# H3 register map
Vendor: Allwinner; Series: H3; File version: 0.1
CPU: 0, little endian, MPU, no FPU, 0 interrupt priority bits
Registers are 32-bit, read-write, reset 0x0 unless marked. A register's access mark holds for its fields unless they carry their own. Offsets are from the block's base; [hi:lo] are bit positions.

## SD/MMC0
Base 0x01C0F000
Same registers: SD/MMC1 0x01C10000, SD/MMC2 0x01C11000
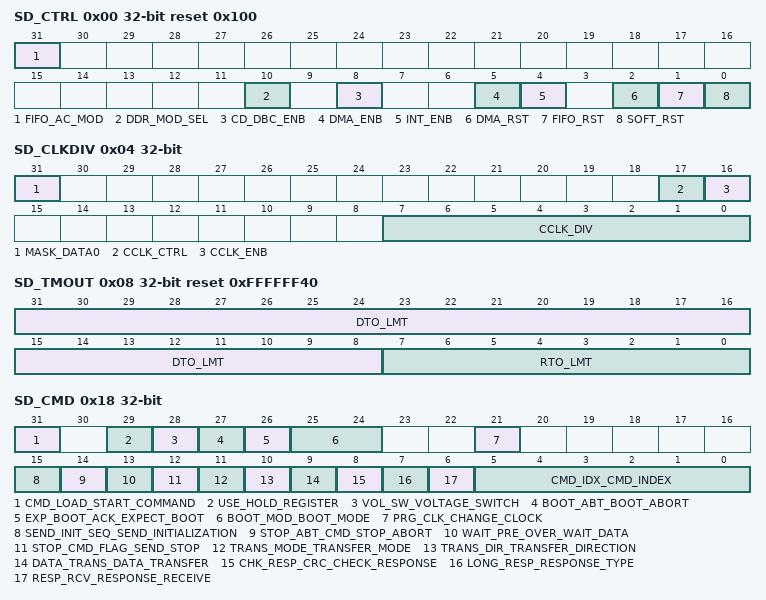
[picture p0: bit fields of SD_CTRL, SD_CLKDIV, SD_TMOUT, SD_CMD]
0x00 SD_CTRL reset 0x100
  [31] FIFO_AC_MOD — FIFO Access Mode 1-AHB bus 0-DMA bus
  [10] DDR_MOD_SEL — DDR Mode Select 0 - SDR mode 1 - DDR mode
  [8] CD_DBC_ENB — Card Detect (Data[3] status) De-bounce Enable 0 - disable de-bounce 1 - enable de-bounce
  [5] DMA_ENB — DMA Global Enable 0 - Disable DMA to transfer data, using AHB bus 1 - Enable DMA to transfer data
  [4] INT_ENB — Global Interrupt Enable 0 - Disable interrupts 1 - Enable interrupts
  [2] DMA_RST — DMA Reset
  [1] FIFO_RST — FIFO Reset 0 - No change 1 - Reset FIFO
  [0] SOFT_RST — Software Reset 0 - No change 1 - Reset SD/MMC controller
0x04 SD_CLKDIV
  [31] MASK_DATA0 — 0 - Do not mask data0 when updata clock ; 1 - Mask data0 when updata clock;
  [17] CCLK_CTRL — Card Clock Output Control 0 - Card clock always on 1 - Turn off card clock when FSM in IDLE state
  [16] CCLK_ENB — Card Clock Enable 0 - Card Clock off 1 - Card Clock on
  [7:0] CCLK_DIV — Card clock divider n - Source clock is divided by 2*n.(n=0~255)
0x08 SD_TMOUT reset 0xFFFFFF40
  [31:8] DTO_LMT — Data Timeout Limit
  [7:0] RTO_LMT — Response Timeout Limit
0x0C SD_CTYPE
  [1:0] CARD_WID — Card width 2`b00 - 1-bit width 2`b01 - 4-bit width 2`b1x - 8-bit width
0x10 SD_BLKSIZ reset 0x200
  [15:0] BLK_SZ — Block size
0x14 SD_BYTCNT reset 0x200
  [31:0] BYTE_CNT — Byte counter Number of bytes to be transferred; should be integer multiple of Block Size for block transfers.
0x18 SD_CMD
  [31] CMD_LOAD_START_COMMAND — CMD_LOAD Start Command. This bit is auto cleared when current command is sent. If there is no any response error happened, a command complete interrupt bit (CMD_OVER) will be set in interrupt register. You should not write any other command before this bit is cleared, or a command busy interrupt bit (CMD_BUSY) will be set in interrupt register.
  [29] USE_HOLD_REGISTER — Use Hold Register 0 - CMD and DATA sent to card bypassing HOLD Register 1 - CMD and DATA sent to card through the HOLD Register
  [28] VOL_SW_VOLTAGE_SWITCH — VOL_SW Voltage Switch 0 - normal command 1 - Voltage switch command, set for CMD11 only
  [27] BOOT_ABT_BOOT_ABORT — BOOT_ABT Boot Abort Setting this bit will terminate the boot operation.
  [26] EXP_BOOT_ACK_EXPECT_BOOT — EXP_BOOT_ACK Expect Boot Acknowledge. When Software sets this bit along in mandatory boot operation, controller expects a boot acknowledge start pattern of 0-1-0 from the selected card.
  [25:24] BOOT_MOD_BOOT_MODE — BOOT_MOD Boot Mode 2`b00 - normal command 2`b01 - Mandatory Boot operation 2`b10 - Alternate Boot operation 2`b11 - reserved
  [21] PRG_CLK_CHANGE_CLOCK — PRG_CLK Change Clock 0 - Normal command 1 - Change Card Clock; when this bit is set, controller will change clock domain and clock output. No command will be sent.
  [15] SEND_INIT_SEQ_SEND_INITIALIZATION — SEND_INIT_SEQ Send Initialization 0 - normal command sending 1 - Send initialization sequence before sending this command.
  [14] STOP_ABT_CMD_STOP_ABORT — STOP_ABT_CMD Stop Abort Command 0 - normal command sending 1 - send Stop or abort command to stop current data transfer in progress.(CMD12, CMD52 for writing `I/O Abort` in SDIO CCCR)
  [13] WAIT_PRE_OVER_WAIT_DATA — WAIT_PRE_OVER Wait Data Transfer Over 0 - Send command at once, do not care of data transferring 1 - Wait for data transfer completion before sending current command
  [12] STOP_CMD_FLAG_SEND_STOP — STOP_CMD_FLAG Send Stop CMD Automatically (CMD12) 0 - Do not send stop command at end of data transfer 1 - Send stop command automatically at end of data transfer
  [11] TRANS_MODE_TRANSFER_MODE — TRANS_MODE Transfer Mode 0 - Block data transfer command 1 - Stream data transfer command
  [10] TRANS_DIR_TRANSFER_DIRECTION — TRANS_DIR Transfer Direction 0 - Read operation 1 - Write operation
  [9] DATA_TRANS_DATA_TRANSFER — DATA_TRANS Data Transfer 0 - without data transfer 1 - with data transfer
  [8] CHK_RESP_CRC_CHECK_RESPONSE — CHK_RESP_CRC Check Response CRC 0 - Do not check response CRC 1 - Check response CRC
  [7] LONG_RESP_RESPONSE_TYPE — LONG_RESP Response Type 0 -Short Response (48 bits) 1 -Long Response (136 bits)
  [6] RESP_RCV_RESPONSE_RECEIVE — RESP_RCV Response Receive 0 - Command without Response 1 - Command with Response
  [5:0] CMD_IDX_CMD_INDEX — CMD_IDX CMD Index Command index value
0x1C SD_CMDARG
  [31:0] CMD_ARG — Command argument
0x20 SD_RESP0 — Response 0 register
  [31:0] CMD_RESP0 ro — response 0 Bit[31:0] of response
0x24 SD_RESP1 — Response 1 register
  [31:0] CMD_RESP1 ro — response 1 Bit[63:31] of response
0x28 SD_RESP2 — Response 2 register
  [31:0] CMD_RESP2 ro — response 2 Bit[95:64] of response
0x2C SD_RESP3 — Response 3 register
  [31:0] CMD_RESP3 ro — response 3 Bit[127:96] of response
0x30 SD_INTMASK
  [31:0] INT_MASK — 0 - interrupt masked 1 - interrupt enabled Bit field defined as following: bit 31- card removed bit 30 - card inserted bit 17~29 - reserved bit 16 - SDIO interrupt bit 15 - Data End-bit error bit 14 - Auto Stop Command done bit 13 - Data Start Error bit 12 - Command Busy and illegal write bit 11 - FIFO under run/overflow bit 10 - Data starvation timeout /V1.8 Switch Done bit 9 - Data timeout/Boot data start bit 8 - Response timeout/Boot ACK received bit 7 - Data CRC error bit 6 - Response CRC error bit 5 - Data Receive Request bit 4 -Data Transmit Request bit 3 - Data Transfer Complete bit 2 - Command Complete bit 1 - Response Error (no response or response CRC error) bit 0 - Reserved
0x34 SD_MINTSTS
  [31:0] MSKD_ISTA ro — Interrupt status. Enabled only if corresponding bit in mask register is set. Bit field defined as following: bit 31 - card removed bit 30 - card inserted bit 17~29 - reserved bit 16 - SDIO interrupt bit 15 - Data End-bit error bit 14 - Auto command done bit 13 - Data Start Error bit 12 - Command Busy and illegal write bit 11 - FIFO under run/overflow bit 10 - Data starvation timeout (HTO)/V1.8 Switch Done bit 9 - Data timeout/Boot data start bit 8 - Response timeout/Boot ACK received bit 7 - Data CRC error bit 6 - Response CRC error bit 5 - Data Receive Request bit 4 -Data Transmit Request bit 3 - Data Transfer Complete bit 2 - Command Complete bit 1 - Response Error (no response or response CRC error) bit 0 - Reserved
0x38 SD_RINTSTS
  [31:0] RAW_ISTA — Raw Interrupt Status. Bit field defined as following: bit 31 - card removed bit 30 - card inserted bit 17~29 - reserved bit 16 - SDIO interrupt bit 15 - Data End-bit error bit 14 - Auto command done bit 13 - Data Start Error bit 12 - Command Busy and illegal write bit 11 - FIFO under run/overflow bit 10 - Data starvation timeout (HTO)/V1.8 Switch Done bit 9 - Data timeout/Boot data start bit 8 - Response timeout/Boot ACK received bit 7 - Data CRC error bit 6 - Response CRC error bit 5 - Data Receive Request bit 4 -Data Transmit Request bit 3 - Data Transfer Complete bit 2 - Command Complete bit 1 - Response Error (no response or response CRC error) bit 0 - Reserved
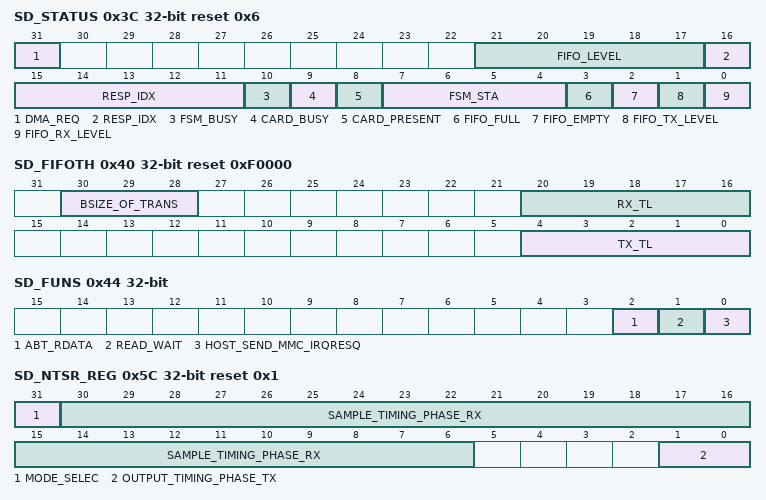
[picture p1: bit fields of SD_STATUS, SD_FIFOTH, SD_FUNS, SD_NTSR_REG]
0x3C SD_STATUS reset 0x6
  [31] DMA_REQ ro — dma_req DMA request signal state
  [21:17] FIFO_LEVEL ro — FIFO Level Number of filled locations in FIFO
  [16:11] RESP_IDX ro — Response Index Index of previous response, including any auto-stop sent by controller
  [10] FSM_BUSY ro — Data FSM Busy Data transmit or receive state-machine is busy
  [9] CARD_BUSY ro — Card data busy Inverted version of DATA[0] 0 - card data not busy 1 - card data busy
  [8] CARD_PRESENT ro — Data[3] status level of DATA[3]; checks whether card is present 0 - card not present 1 - card present
  [7:4] FSM_STA ro — Command FSM states: 0 - Idle 1 - Send init sequence 2 - Tx cmd start bit 3 - Tx cmd tx bit 4 - Tx cmd index + arg 5 - Tx cmd crc7 6 - Tx cmd end bit 7 - Rx resp start bit 8 - Rx resp IRQ response 9 - Rx resp tx bit 10 - Rx resp cmd idx 11 - Rx resp data 12 - Rx resp crc7 13 - Rx resp end bit 14 - Cmd path wait NCC 15 - Wait; CMD-to-response turnaround
  [3] FIFO_FULL ro — FIFO full 1 - FIFO full 0 - FIFO not full
  [2] FIFO_EMPTY ro — FIFO Empty 1 - FIFO Empty 0 - FIFO not Empty
  [1] FIFO_TX_LEVEL ro — FIFO TX Water Level flag 0 - FIFO didn`t reach transmit trigger level 1 - FIFO reached transmit trigger level
  [0] FIFO_RX_LEVEL ro — FIFO TX Water Level flag 0 - FIFO didn`t reach receive trigger level 1 - FIFO reached receive trigger level
0x40 SD_FIFOTH reset 0xF0000
  [30:28] BSIZE_OF_TRANS — Burst size of multiple transaction 000 - 1 transfers 001 - 4 010 - 8 011 - 16 100 - 32 101 - 64 110 - 128 111 - 256 Should be programmed same as DMA controller multiple transaction size. The units for transfers are the DWORD. A single transfer would be signaled based on this value. Value should be sub-multiple of (RX_TL + 1) and (FIFO_DEPTH - TX_TL) Recommended: MSize = 8, TX_TL = 16, RX_TL = 15
  [20:16] RX_TL — Rx Trigger Level 0x0~0x1e - RX Trigger Level is 0~30 0x1f - reserved FIFO threshold when FIFO request host to receive data from FIFO. When FIFO data level is greater than this value, DMA is request is raised if DMA enabled, or RX interrupt bit is set if interrupt enabled. At the end of packet, if the last transfer is less than this level, the value is ignored and relative request will be raised as usual. Recommended: 15 (means greater than 15)
  [4:0] TX_TL — TX Trigger Level 0x1~0xf - TX Trigger Level is 1~31 0x0 - no trigger FIFO threshold when FIFO requests host to transmit data to FIFO. When FIFO data level is less than or equal to this value, DMA TX request is raised if DMA enabled, or TX request interrupt bit is set if interrupt enabled. At the end of packet, if the last transfer is less than this level, the value is ignored and relative request will be raised as usual. Recommended: 16 (means less than or equal to 16)
0x44 SD_FUNS — FIFO Function Select register
  [2] ABT_RDATA — Abort Read Data 0 - Ignored 1- After suspend command is issued during read-transfer, software polls card to find when suspend happened. Once suspend occurs, software sets bit to reset data state-machine, which is waiting for next block of data. Used in SDIO card suspends sequence. .
  [1] READ_WAIT — Read Wait 0 - Clear SDIO read wait 1 - Assert SDIO read wait
  [0] HOST_SEND_MMC_IRQRESQ — Host Send MMC IRQ Response 0 - Ignored 1 - Send auto IRQ response When host is waiting MMC card interrupt response, setting this bit will make controller cancel wait state and return to idle state, at which time, controller will receive IRQ response sent by itself.
0x58 SD_A12A reset 0xFFFF — Auto command 12 argument
  [15:0] SD_A12A — SD_A12A set the argument of command 12 automatically send by controller
0x5C SD_NTSR_REG reset 0x1
  [31] MODE_SELEC — 0 - Old mode of Sample/Output Timing ; 1 - New mode of Sample/Output Timing; Default : 0;
  [30:6] SAMPLE_TIMING_PHASE_RX — SAMPLE_TIMING_PHASE(RX) 00 - Sample timing phase offset 90 ; 01 - Sample timing phase offset 180 ; 10 - Sample timing phase offset 270 ; 11 - Ignore; Default : 00;
  [1:0] OUTPUT_TIMING_PHASE_TX — OUTPUT_TIMING_PHASE(TX) 00 - Output timing phase offset 90 ; 01 - Output timing phase offset 180 ; 10 - Output timing phase offset 270 ; 11 - Ignore; Default : 01;
0x78 SD_HWRST reset 0x1 — Hardware Reset Register
  [0] HW_RESET — 1 - Active mode 0 - Reset These bits cause the cards to enter pre-idle state, which requires them to be re-initialized.
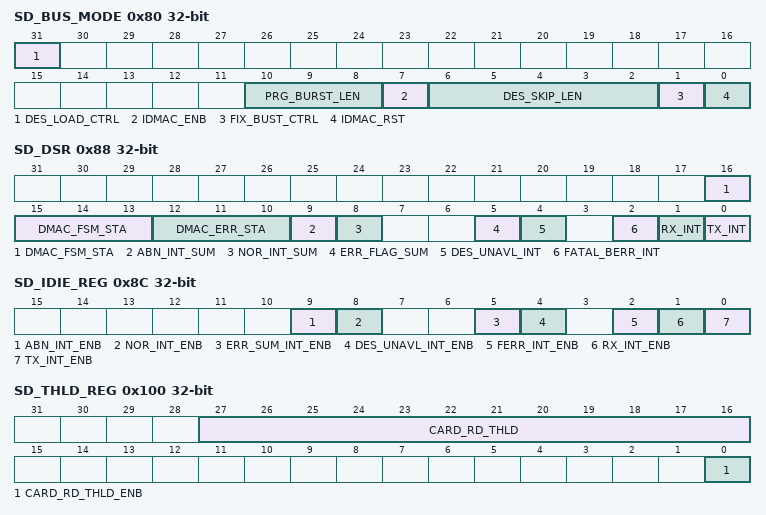
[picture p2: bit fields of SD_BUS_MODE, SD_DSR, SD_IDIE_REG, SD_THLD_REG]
0x80 SD_BUS_MODE
  [31] DES_LOAD_CTRL wo — When DMAC fetches a descriptor, if the valid bit of a descriptor is not set, DMAC FSM will go to the suspend state. Setting this bit will make DMAC re-fetch descriptor again and do the transfer normally.
  [10:8] PRG_BURST_LEN ro — Programmable Burst Length. These bits indicate the maximum number of beats to be performed in one IDMAC transaction. The IDMAC will always attempt to burst as specified in PBL each time it starts a Burst transfer on the host bus. The permissible values are 1, 4, 8, 16, 32, 64, 128 and 256. This value is the mirror of MSIZE of FIFOTH register. In order to change this value, write the required value to FIFOTH register. This is an encode value as follows. 000 - 1 transfers 001 - 4 transfers 010 - 8 transfers 011 - 16 transfers 100 - 32 transfers 101 - 64 transfers 110 - 128 transfers 111 - 256 transfers Transfer unit is either 16, 32, or 64 bits, based on HDATA_WIDTH. PBL is a read-only value.
  [7] IDMAC_ENB — IDMAC Enable. When set, the IDMAC is enabled. DE is read/write.
  [6:2] DES_SKIP_LEN — Descriptor Skip Length. Specifies the number of Word to skip between two unchained descriptors. This is applicable only for dual buffer structure. Default is set to 4 DWORD.
  [1] FIX_BUST_CTRL — Fixed Burst. Controls whether the AHB Master interface performs fixed burst transfers or not. When set, the AHB will use only SINGLE, INCR4, INCR8 during start of normal burst transfers. When reset, the AHB will use SINGLE and INCR burst transfer operations.
  [0] IDMAC_RST — DMA Reset. When set, the DMA Controller resets all its internal registers. SWR is read/write. It is automatically cleared after 1 clock cycle.
0x84 SD_DLBA — Descriptor List Base Address
  [31:0] DES_BASE_ADDR — Start of Descriptor List. Contains the base address of the First Descriptor. The LSB bits [1:0] are ignored and taken as all-zero by the IDMAC internally. Hence these LSB bits are read-only.
0x88 SD_DSR
  [16:13] DMAC_FSM_STA ro — DMAC FSM present state. 0 - DMA_IDLE 1 - DMA_SUSPEND 2 - DESC_RD 3 - DESC_CHK 4 - DMA_RD_REQ_WAIT 5 - DMA_WR_REQ_WAIT 6 - DMA_RD 7 - DMA_WR 8 - DESC_CLOSE This bit is read-only.
  [12:10] DMAC_ERR_STA ro — Error Bits. Indicates the type of error that caused a Bus Error. Valid only with Fatal Bus Error bit (IDSTS[2]) set. This field does not generate an interrupt. 3`b001 - Host Abort received during transmission 3`b010 - Host Abort received during reception Others: Reserved EB is read-only.
  [9] ABN_INT_SUM — Abnormal Interrupt Summary. Logical OR of the following: IDSTS[2] - Fatal Bus Interrupt IDSTS[4] - DU bit Interrupt IDSTS[5] - Card Error Summary Interrupt Only unmasked bits affect this bit. This is a sticky bit and must be cleared each time a corresponding bit that causes AIS to be set is cleared. Writing a 1 clears this bit.
  [8] NOR_INT_SUM — Normal Interrupt Summary. Logical OR of the following: IDSTS[0] - Transmit Interrupt IDSTS[1] - Receive Interrupt Only unmasked bits affect this bit. This is a sticky bit and must be cleared each time a corresponding bit that causes NIS to be set is cleared. Writing a 1 clears this bit.
  [5] ERR_FLAG_SUM — Card Error Summary. Indicates the status of the transaction to/from the card; also present in RINTSTS. Indicates the logical OR of the following bits: EBE - End Bit Error RTO - Response Timeout/Boot Ack Timeout RCRC - Response CRC SBE - Start Bit Error DRTO - Data Read Timeout/BDS timeout DCRC - Data CRC for Receive RE - Response Error
  [4] DES_UNAVL_INT — Descriptor Unavailable Interrupt. This bit is set when the descriptor is unavailable due to OWN bit = 0 (DES0[31] =0). Writing a 1 clears this bit.
  [2] FATAL_BERR_INT — Fatal Bus Error Interrupt. Indicates that a Bus Error occurred (IDSTS[12:10]). When this bit is set, the DMA disables all its bus accesses. Writing a 1 clears this bit.
  [1] RX_INT — Receive Interrupt. Indicates the completion of data reception for a descriptor. Writing a 1 clears this bit.
  [0] TX_INT — Transmit Interrupt. Indicates that data transmission is finished for a descriptor. Writing a `1` clears this bit.
0x8C SD_IDIE_REG
  [9] ABN_INT_ENB — Abnormal Interrupt Summary Enable. When set, an abnormal interrupt is enabled. This bit enables the following bits: IDINTEN[2] - Fatal Bus Error Interrupt IDINTEN[4] - DU Interrupt IDINTEN[5] - Card Error Summary Interrupt
  [8] NOR_INT_ENB — Normal Interrupt Summary Enable. When set, a normal interrupt is enabled. When reset, a normal interrupt is disabled. This bit enables the following bits: IDINTEN[0] - Transmit Interrupt IDINTEN[1] - Receive Interrupt
  [5] ERR_SUM_INT_ENB — Card Error summary Interrupt Enable. When set, it enables the Card Interrupt summary.
  [4] DES_UNAVL_INT_ENB — Descriptor Unavailable Interrupt. When set along with Abnormal Interrupt Summary Enable, the DU interrupt is enabled.
  [2] FERR_INT_ENB — Fatal Bus Error Enable. When set with Abnormal Interrupt Summary Enable, the Fatal Bus Error Interrupt is enabled. When reset, Fatal Bus Error Enable Interrupt is disabled.
  [1] RX_INT_ENB — Receive Interrupt Enable. When set with Normal Interrupt Summary Enable, Receive Interrupt is enabled. When reset, Receive Interrupt is disabled.
  [0] TX_INT_ENB — Transmit Interrupt Enable. When set with Normal Interrupt Summary Enable, Transmit Interrupt is enabled. When reset, Transmit Interrupt is disabled.
0x100 SD_THLD_REG
  [27:16] CARD_RD_THLD — Card Read Threshold Size
  [0] CARD_RD_THLD_ENB — Card Read Threshold Enable 0 - Card Read Threshold Disable 1 - Card Read Threshold Enable Host controller initiates Read Transfer only if CARD_RD_THLD amount of space is available in receive FIFO
0x10C EMMC_DDR_SBIT_DET_REG
  [0] HALF_START_BIT — Control for start bit detection mechanism inside mstorage based on duration of start bit. For eMMC 4.41, start bit can be: 0 - Full cycle 1 - Less than one full cycle Set HALF_START_BIT=1 for eMMC 4.41 and above; set to 0 for SD applications.
0x110 RESP_CRC_REG
  [6:0] RESP_CRC ro — Response CRC Response CRC from card/eMMC.
0x114 DATA7_CRC_REG
  [31:0] DATA7_CRC ro — Data[7] CRC CRC in data[7] from card/eMMC.In DDR mode,the higher 16 bits indicate the CRC of even data,and the lower 16bits indicate the CRC of odd data.In SDR mode,the higher of 16 bits indicate the CRC of all data.
0x118 DATA6_CRC_REG
  [31:0] DATA6_CRC ro — Data[6] CRC CRC in data[6] from card/eMMC.In DDR mode,the higher 16 bits indicate the CRC of even data,and the lower 16bits indicate the CRC of odd data.In SDR mode,the higher of 16 bits indicate the CRC of all data.
0x11C DATA5_CRC_REG
  [31:0] DATA5_CRC ro — Data[5] CRC CRC in data[5] from card/eMMC.In DDR mode,the higher 16 bits indicate the CRC of even data,and the lower 16bits indicate the CRC of odd data.In SDR mode,the higher of 16 bits indicate the CRC of all data.
0x120 DATA4_CRC_REG
  [31:0] DATA4_CRC ro — Data[4] CRC CRC in data[4] from card/eMMC.In DDR mode,the higher 16 bits indicate the CRC of even data,and the lower 16bits indicate the CRC of odd data.In SDR mode,the higher of 16 bits indicate the CRC of all data.
0x124 DATA3_CRC_REG
  [31:0] DATA3_CRC ro — Data[3] CRC CRC in data[3] from card/eMMC. In 8bit DDR mode,the higher 16 bits indicate the CRC of even data,and the lower 16bits indicate the CRC of odd data. In 4 bit DDR mode,the higher of 16 bits indicate the CRC of odd data, ,and the lower 16bits indicate the CRC of even data. In SDR mode,the higher of 16 bits indicate the CRC of all data.
0x128 DATA2_CRC_REG
  [31:0] DATA2_CRC ro — Data[2] CRC CRC in data[2] from card/eMMC. In 8bit DDR mode,the higher 16 bits indicate the CRC of even data,and the lower 16bits indicate the CRC of odd data. In 4 bit DDR mode,the higher of 16 bits indicate the CRC of odd data, ,and the lower 16bits indicate the CRC of even data. In SDR mode,the higher of 16 bits indicate the CRC of all data.
0x12C DATA1_CRC_REG
  [31:0] DATA1_CRC ro — Data[1] CRC CRC in data[1] from card/eMMC. In 8bit DDR mode,the higher 16 bits indicate the CRC of even data,and the lower 16bits indicate the CRC of odd data. In 4 bit DDR mode,the higher of 16 bits indicate the CRC of odd data, ,and the lower 16bits indicate the CRC of even data. In SDR mode,the higher of 16 bits indicate the CRC of all data.
0x130 DATA0_CRC_REG
  [31:0] DATA0_CRC ro — Data[0] CRC CRC in data[0] from card/eMMC. In 8bit DDR mode,the higher 16 bits indicate the CRC of even data,and the lower 16bits indicate the CRC of odd data. In 4 bit DDR mode,the higher of 16 bits indicate the CRC of odd data, ,and the lower 16bits indicate the CRC of even data. In SDR mode,the higher of 16 bits indicate the CRC of all data.
0x134 CRC_STA_REG
  [2:0] CRC_STA ro — CRC Status CRC status from card/eMMC in write operation Positive CRC status token:3`b010 Negative CRC status token:3`b101
0x200 SD_FIFO_REG
  [31:0] TX/RX_FIFO — Data FIFO
